# DSS0_VID1 register map
Vendor: Texas Instruments
Peripheral module from a debugger description file (folder J7ES).
Registers are 32-bit, access per field, reset 0x0 unless marked. A register's access mark holds for its fields unless they carry their own. Offsets are as the file gives them; lines under a group give offsets from that group; [hi:lo] are bit positions; {n}, {i} and the like mark numbered series; 'fields as' and 'values as' point back to an identical list; <NAME> marks a mode.

## DSS0_VID1
0x00 DSS0_VID_ACCUH_0 — The register configures the resize accumulator init values for horizontal up/down-sampling of the video window. DISPC_VIDx_ACCU__0 & DISPC_VIDx_ACCU__1 for ping-pong mechanism with external trigger, based on the field polarity. This register is used for ARGB and Y in YUV420/YUV422. Shadow register
  [23:0] HORIZONTALACCU rw — Horizontal initialization accu signed value
0x04 DSS0_VID_ACCUH_1 — The register configures the resize accumulator init values for horizontal up/down-sampling of the video window. DISPC_VIDx_ACCU__0 & DISPC_VIDx_ACCU__1 for ping-pong mechanism with external trigger, based on the field polarity. This register is used for ARGB and Y in YUV420/YUV422. Shadow register
  fields as DSS0_VID_ACCUH_0
0x08 DSS0_VID_ACCUH2_0 — The register configures the resize accumulator init value for horizontal up/down-sampling of the video window. DISPC_VID n_ACCU2__0 & DISPC_VID n_ACCU2__1 for ping-pong mechanism with external trigger, based on the field polarity. This register is used for U/V components in YUV420/YUV422. It is not used when the input format is any RGB format. Shadow register
  fields as DSS0_VID_ACCUH_0
0x0C DSS0_VID_ACCUH2_1 — The register configures the resize accumulator init value for horizontal up/down-sampling of the video window. DISPC_VID n_ACCU2__0 & DISPC_VID n_ACCU2__1 for ping-pong mechanism with external trigger, based on the field polarity. This register is used for U/V components in YUV420/YUV422. It is not used when the input format is any RGB format. Shadow register
  fields as DSS0_VID_ACCUH_0
0x10 DSS0_VID_ACCUV_0 — The register configures the resize accumulator init values for horizontal and vertical up/down-sampling of the video window. DISPC_VIDx_ACCU__0 & DISPC_VIDx_ACCU__1 for ping-pong mechanism with external trigger, based on the field polarity. It is used for ARGB and Y in YUV420/YUV422. Shadow register
  [23:0] VERTICALACCU rw — Vertical initialization accu signed value
0x14 DSS0_VID_ACCUV_1 — The register configures the resize accumulator init values for horizontal and vertical up/down-sampling of the video window. DISPC_VIDx_ACCU__0 & DISPC_VIDx_ACCU__1 for ping-pong mechanism with external trigger, based on the field polarity. It is used for ARGB and Y in YUV420/YUV422. Shadow register
  [23:0] VERTICALACCU rw — Vertical initialization accu signed value
0x18 DSS0_VID_ACCUV2_0 — The register configures the resize accumulator init value for vertical up/down-sampling of the video window. ACCU2__0 & ACCU2__1 for ping-pong mechanism with external trigger, based on the field polarity. It is used for U/V components for YUV420. It is not used when the input format is any RGB format or YUV422. Shadow register
  [23:0] VERTICALACCU rw — Vertical initialization accu signed value
0x1C DSS0_VID_ACCUV2_1 — The register configures the resize accumulator init value for vertical up/down-sampling of the video window. ACCU2__0 & ACCU2__1 for ping-pong mechanism with external trigger, based on the field polarity. It is used for U/V components for YUV420. It is not used when the input format is any RGB format or YUV422. Shadow register
  [23:0] VERTICALACCU rw — Vertical initialization accu signed value
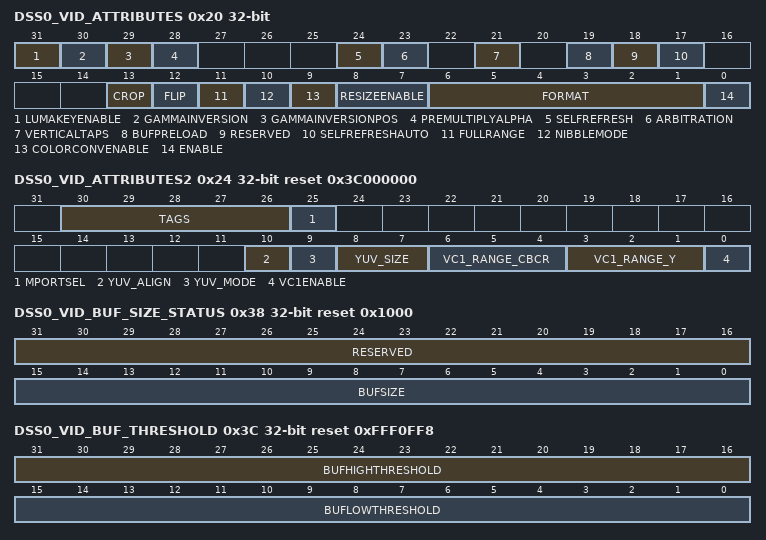
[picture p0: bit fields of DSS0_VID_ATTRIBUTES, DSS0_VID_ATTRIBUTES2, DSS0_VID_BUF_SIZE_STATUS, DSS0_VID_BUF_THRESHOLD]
0x20 DSS0_VID_ATTRIBUTES — The register configures the of the video window. Shadow register
  [31] LUMAKEYENABLE rw — Enable Luma Key transparency matching
  [30] GAMMAINVERSION rw — Inverse Gamma support [using the CLUT table]
  [29] GAMMAINVERSIONPOS rw — Position of Inverse Gamma operation
  [28] PREMULTIPLYALPHA rw — The field configures the DISPC VID to process incoming data as premultiplied alpha data or non premultiplied alpha data.
  [24] SELFREFRESH rw — Enables the self refresh of the video window, from its own DMA buffer only
  [23] ARBITRATION rw — Determines the priority of the video pipeline.
  [21] VERTICALTAPS rw — Video Vertical Resize Tap Number.
  [19] BUFPRELOAD rw — Video
  [18] RESERVED ro — Write 0's for future compatibility.
  [17] SELFREFRESHAUTO rw — Automatic self refresh mode
  [13] CROP rw — Enables cropping operation at the output of Video Pipeline
  [12] FLIP rw — Describes the frame buffer flip operation
  [11] FULLRANGE rw — Color Space Conversion full range setting
  [10] NIBBLEMODE rw — Video Nibble mode [only for
  [9] COLORCONVENABLE rw — Enable the color space conversion.
  [8:7] RESIZEENABLE rw — Video Resize Enable
  [6:1] FORMAT rw — Video Format.
  [0] ENABLE rw — Video pipeline Enable
0x24 DSS0_VID_ATTRIBUTES2 reset 0x3C000000 — The register configures the of the video window. Shadow register
  [30:26] TAGS rw — Number of OCP TAGS to be used for the pipeline [from 0x0 to 0xF].
  [25] MPORTSEL rw — Master-Port Selection.
  [10] YUV_ALIGN rw — Alignment [MSB or LSB align] for unpacked 10b/12b YUV data
  [9] YUV_MODE rw — Mode of packing for YUV data [only for 10b/12b formats]
  [8:7] YUV_SIZE rw
  [6:4] VC1_RANGE_CBCR rw — Defines the VC1 range value for the CbCr component from 0 to 7
  [3:1] VC1_RANGE_Y rw — Defines the VC1 range value for the Y component from 0 to 7
  [0] VC1ENABLE rw — Enable/disable the VC1 range mapping processing.
0x28 DSS0_VID_BA_0 rw — The register configures the base address of the single video buffer. In case of single plane ARGB or YUV, this is the BA. In case of two plane YUV, this is the BA_Y. In case of two plane RGB565-A8, this is the BA_Alpha. BA__0 & BA__1 for ping-pong mechanism with external trigger, based on the field polarity otherwise only BA__0 is used. Shadow register
  [31:0] BA — Video base address.
0x2C DSS0_VID_BA_1 rw — The register configures the base address of the single video buffer. In case of single plane ARGB or YUV, this is the BA. In case of two plane YUV, this is the BA_Y. In case of two plane RGB565-A8, this is the BA_Alpha. BA__0 & BA__1 for ping-pong mechanism with external trigger, based on the field polarity otherwise only BA__0 is used. Shadow register
  [31:0] BA — Video base address.
0x30 DSS0_VID_BA_UV_0 rw — The register configures the base address of the UV buffer for two plane YUV or RGB buffer for two plane RGB565-A8, for the video window. BA_UV__0 & BA_UV__1 for ping-pong mechanism with external trigger, based on the field polarity otherwise only BA_UV__0 is used. Shadow register
  [31:0] BA — Video base address aligned on 16-bit boundary Base address of the UV video buffer used only in case of YUV420-NV12
0x34 DSS0_VID_BA_UV_1 rw — The register configures the base address of the UV buffer for two plane YUV or RGB buffer for two plane RGB565-A8, for the video window. BA_UV__0 & BA_UV__1 for ping-pong mechanism with external trigger, based on the field polarity otherwise only BA_UV__0 is used. Shadow register
  fields as DSS0_VID_BA_UV_0
0x38 DSS0_VID_BUF_SIZE_STATUS ro reset 0x1000 — The register returns the Video buffer for the video pipeline
  [31:16] RESERVED — Write 0's for future compatibility Reads return 0
  [15:0] BUFSIZE — Video DMA buffer
0x3C DSS0_VID_BUF_THRESHOLD rw reset 0xFFF0FF8 — The register configures the video buffer associated with the video pipeline. Shadow register
  [31:16] BUFHIGHTHRESHOLD — DMA buffer High Threshold.
  [15:0] BUFLOWTHRESHOLD — DMA buffer Low Threshold.
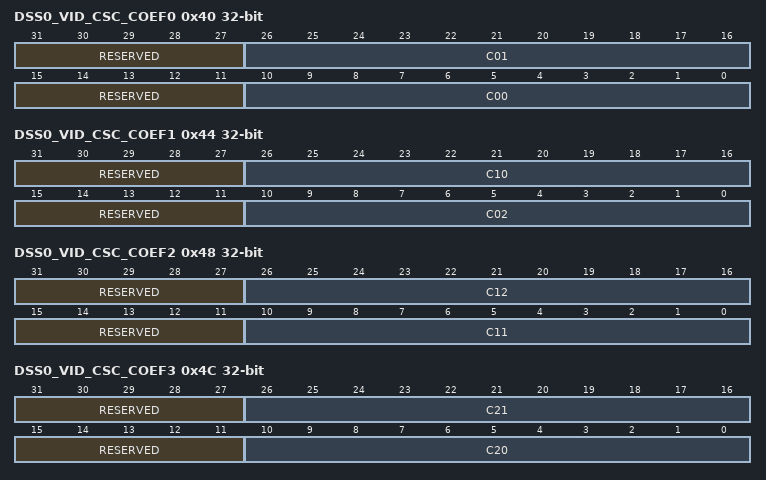
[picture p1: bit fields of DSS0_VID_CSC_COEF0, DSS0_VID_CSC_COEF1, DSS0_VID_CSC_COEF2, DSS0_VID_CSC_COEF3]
0x40 DSS0_VID_CSC_COEF0 — The register configures the color space conversion matrix coefficients. Shadow register
  [31:27] RESERVED ro — Write 0's for future compatibility Reads return 0
  [26:16] C01 rw — C01 Coefficient.
  [15:11] RESERVED ro — Write 0's for future compatibility Reads return 0
  [10:0] C00 rw — C00 Coefficient.
0x44 DSS0_VID_CSC_COEF1 — The register configures the color space conversion matrix coefficients. Shadow register
  [31:27] RESERVED ro — Write 0's for future compatibility Reads return 0
  [26:16] C10 rw — C10 Coefficient.
  [15:11] RESERVED ro — Write 0's for future compatibility Reads return 0
  [10:0] C02 rw — C02 Coefficient.
0x48 DSS0_VID_CSC_COEF2 — The register configures the color space conversion matrix coefficients. Shadow register
  [31:27] RESERVED ro — Write 0's for future compatibility Reads return 0
  [26:16] C12 rw — C12 Coefficient.
  [15:11] RESERVED ro — Write 0's for future compatibility Reads return 0
  [10:0] C11 rw — C11 Coefficient.
0x4C DSS0_VID_CSC_COEF3 — The register configures the color space conversion matrix coefficients. Shadow register
  [31:27] RESERVED ro — Write 0's for future compatibility Reads return 0
  [26:16] C21 rw — C21 coefficient.
  [15:11] RESERVED ro — Write 0's for future compatibility Reads return 0
  [10:0] C20 rw — C20 coefficient.
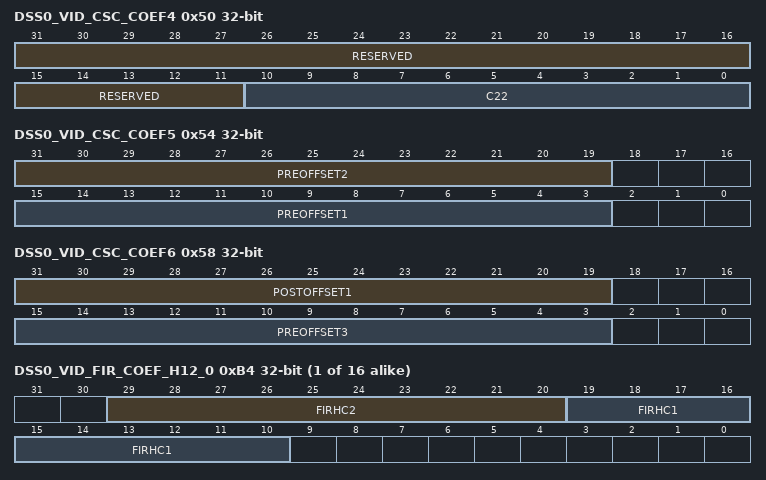
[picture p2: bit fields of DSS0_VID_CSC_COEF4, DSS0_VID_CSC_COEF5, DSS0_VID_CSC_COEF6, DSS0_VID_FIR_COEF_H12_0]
0x50 DSS0_VID_CSC_COEF4 — The register configures the color space conversion matrix coefficients. Shadow register
  [31:11] RESERVED ro — Write 0's for future compatibility Reads return 0
  [10:0] C22 rw — C22 Coefficient.
0x54 DSS0_VID_CSC_COEF5 — The register configures the color space conversion matrix coefficients. Shadow register
  [31:19] PREOFFSET2 rw — Row-2 pre-offset.
  [15:3] PREOFFSET1 rw — Row1 pre-offset.
0x58 DSS0_VID_CSC_COEF6 — The register configures the color space conversion matrix coefficients. Shadow register
  [31:19] POSTOFFSET1 rw — Row-1 post-offset.
  [15:3] PREOFFSET3 rw — Row-3 pre-offset.
0x5C DSS0_VID_FIRH reset 0x200000 — The register configures the resize factor for horizontal up/down-sampling of the video window. It is used for ARGB and Y setting. Shadow register
  [23:0] FIRHINC rw — Horizontal increment of the up/down-sampling filter.
0x60 DSS0_VID_FIRH2 reset 0x200000 — The register configures the resize factor for horizontal up/down-sampling of the video window. It is used for U/V components for YUV 422 and 420 input formats. It is not used if input format is any RGB format. Shadow register
  [23:0] FIRHINC rw — Horizontal increment of the up/down-sampling filter for Cb and Cr.
0x64 DSS0_VID_FIRV reset 0x200000 — The register configures the resize factor for vertical up/down-sampling of the video window. It is used for ARGB and Y setting. Shadow register
  [23:0] FIRVINC rw — Vertical increment of the up/down-sampling filter.
0x68 DSS0_VID_FIRV2 reset 0x200000 — The register configures the resize factor for vertical up/down-sampling of the video window. It is used for U/V components for YUV420 input format. It is not used when the input format is any RGB format or YUV422 format. Shadow register.
  [23:0] FIRVINC rw — Vertical increment of the up/down-sampling filter for Cb and Cr.
{0x6C+4i} DSS0_VID_FIR_COEF_H0_{i} (i=0..8) — The bank of registers configures the up/down-scaling coefficients for the horizontal resize of the video picture associated with the video window for the 16 phases. It is used for ARGB and Y setting. Shadow register
  [9:0] FIRHC0 rw — Unsigned coefficient C0 for the horizontal up/down-scaling with the phase {i}
{0x90+4i} DSS0_VID_FIR_COEF_H0_C_{i} (i=0..8) — The bank of registers configures the up/down-scaling coefficients for the horizontal resize of the video picture associated with the video window for the phases from 0 to 15. It is used for Crb and Cr setting. It is used only when the pixel format at the input of the filter is one of the YUV formats. When the register is not used by the HW, any value can be used for the bit-fields. Shadow register
  fields as DSS0_VID_FIR_COEF_H0_0
{0xB4+4i} DSS0_VID_FIR_COEF_H12_{i} (i=0..15) — The bank of registers configures the up/down-scaling coefficients for the horizontal resize of the video picture associated with the video window for the 16 phases. It is used for ARGB and Y setting. Shadow register
  [29:20] FIRHC2 rw — Signed coefficient C2 for the horizontal up/down-scaling with the phase {i}
  [19:10] FIRHC1 rw — Signed coefficient C1 for the horizontal up/down-scaling with the phase {i}
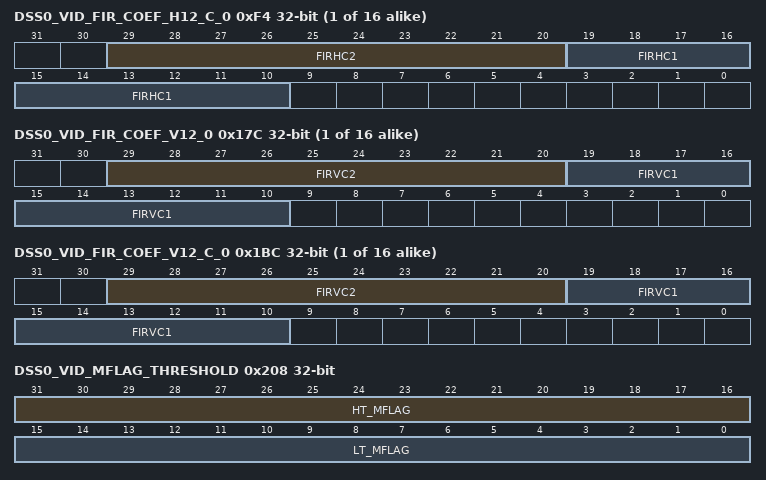
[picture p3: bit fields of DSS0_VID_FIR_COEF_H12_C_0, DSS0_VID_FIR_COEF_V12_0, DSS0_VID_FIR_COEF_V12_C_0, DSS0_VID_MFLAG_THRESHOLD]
{0xF4+4i} DSS0_VID_FIR_COEF_H12_C_{i} (i=0..15) — The bank of registers configures the up/down-scaling coefficients for the horizontal resize of the video picture associated with the video window for the phases from 0 to 15. It is used for Crb and Cr setting. It is used only when the pixel format at the input of the filter is one of the YUV formats. When the register is not used by the HW, any value can be used for the bit-fields. Shadow register
  fields as DSS0_VID_FIR_COEF_H12_0
{0x134+4i} DSS0_VID_FIR_COEF_V0_{i} (i=0..8) — The bank of registers configures the up/down-scaling coefficients for the vertical resize of the video picture associated with the video window for the 16 phases. It is used for ARGB and Y setting. Shadow register
  [9:0] FIRVC0 rw — Unsigned coefficient C0 for the vertical up/down-scaling with the phase {i}
{0x158+4i} DSS0_VID_FIR_COEF_V0_C_{i} (i=0..8) — The bank of registers configures the up/down-scaling coefficients for the vertical resize of the video picture associated with the video window for the phases from 0 to 15. It is used for Crb and Cr setting. It is used only when the pixel format at the input of the filter is one of the YUV formats. When the register is not used by the HW, any value can be used for the bit-fields. Shadow register
  fields as DSS0_VID_FIR_COEF_V0_0
{0x17C+4i} DSS0_VID_FIR_COEF_V12_{i} (i=0..15) — The bank of registers configures the up/down-scaling coefficients for the vertical resize of the video picture associated with the video window for the 16 phases. It is used for ARGB and Y setting. Shadow register
  [29:20] FIRVC2 rw — Signed coefficient C2 for the vertical up/down-scaling with the phase {i}
  [19:10] FIRVC1 rw — Signed coefficient C1 for the vertical up/down-scaling with the phase {i}
{0x1BC+4i} DSS0_VID_FIR_COEF_V12_C_{i} (i=0..15) — The bank of registers configures the up/down-scaling coefficients for the vertical resize of the video picture associated with the video window for the phases from 0 to 15. It is used for Crb and Cr setting. It is used only when the pixel format at the input of the filter is one of the YUV formats. When the register is not used by the HW, any value can be used for the bit-fields. Shadow register
  fields as DSS0_VID_FIR_COEF_V12_0
0x1FC DSS0_VID_GLOBAL_ALPHA reset 0xFF — The register defines the global alpha value for the video pipeline. Shadow register
  [7:0] GLOBALALPHA rw — Global alpha value from 0 to 255.
0x208 DSS0_VID_MFLAG_THRESHOLD rw — Register
  [31:16] HT_MFLAG — MFlag High Threshold
  [15:0] LT_MFLAG — MFlag Low Threshold
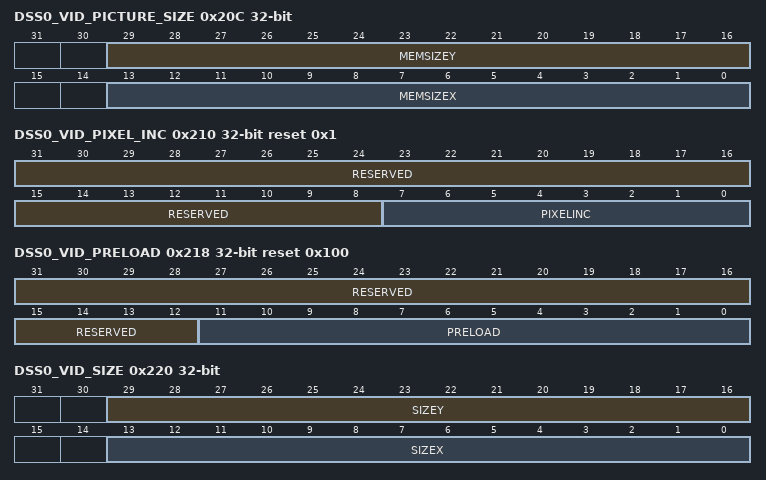
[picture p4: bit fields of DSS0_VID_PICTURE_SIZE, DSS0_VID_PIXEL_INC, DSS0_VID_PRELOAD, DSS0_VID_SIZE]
0x20C DSS0_VID_PICTURE_SIZE rw — The register configures the of the video picture associated with the video layer before up/down-scaling. Shadow register
  [29:16] MEMSIZEY — Number of lines of the video picture Encoded value [from 1 to 16384] to specify the number of lines of the video picture in memory [program to value minus one] When predecimation is set, the value represents the
  [13:0] MEMSIZEX — Number of pixels of the video picture Encoded value [from 1 to 16384] to specify the number of pixels of the video picture in memory [program to value minus one].
0x210 DSS0_VID_PIXEL_INC reset 0x1 — The register configures the number of bytes to increment between two pixels for the buffer associated with the video window. Shadow register
  [31:8] RESERVED ro — Write 0's for future compatibility Reads return 0
  [7:0] PIXELINC rw — Number of bytes to increment between two pixels Encoded unsigned value [from 1 to 255] to specify the number of bytes between two pixels in the video buffer.
0x218 DSS0_VID_PRELOAD reset 0x100 — The register configures the DMA buffer of the video pipeline. Shadow register
  [31:12] RESERVED ro — Write 0's for future compatibility Reads return 0
  [11:0] PRELOAD rw — DMA buffer
0x21C DSS0_VID_ROW_INC rw reset 0x1 — The register configures the number of bytes to increment at the end of the row for the buffer associated with the video window. For YUV420 formats this corresponds to the Y Buffer. Shadow register
  [31:0] ROWINC — Number of bytes to increment at the end of the row Encoded signed value [from -2
0x220 DSS0_VID_SIZE rw — The register configures the of the video window. Shadow register
  [29:16] SIZEY — Number of lines of the video window Encoded value [from 1 to 16384] to specify the number of lines of the video window [program
  [13:0] SIZEX — Number of pixels of the video window Encoded value [from 1 to 16384] to specify the number of pixels of the video window [program
0x22C DSS0_VID_BA_EXT_0 — The register configures the 16-bit base address extension. It is the base-address of the single video buffer for single plane ARGB or YUV. For the Y buffer for two plane YUV. For the Alpha buffer for two plane RGB565-A8. 0 & 1 : For ping-pong mechanism with external trigger, based on the field polarity. Shadow register
  [15:0] BA_EXT rw — Video base address extension [16 bits].
0x230 DSS0_VID_BA_EXT_1 — The register configures the 16-bit base address extension. It is the base-address of the single video buffer for single plane ARGB or YUV. For the Y buffer for two plane YUV. For the Alpha buffer for two plane RGB565-A8. 0 & 1 : For ping-pong mechanism with external trigger, based on the field polarity. Shadow register
  [15:0] BA_EXT rw — Video base address extension [16 bits].
0x234 DSS0_VID_BA_UV_EXT_0 — The register configures the 16-bit base address extension of the UV buffer for two plane YUV or the RGB buffer for two plane RGB565-A8. 0 & 1 : For ping-pong mechanism with external trigger, based on the field polarity. Shadow register
  [15:0] BA_UV_EXT rw — Video base address extension [16 bits].
0x238 DSS0_VID_BA_UV_EXT_1 — The register configures the 16-bit base address extension of the UV buffer for two plane YUV or the RGB buffer for two plane RGB565-A8. 0 & 1 : For ping-pong mechanism with external trigger, based on the field polarity. Shadow register
  [15:0] BA_UV_EXT rw — Video base address extension [16 bits].
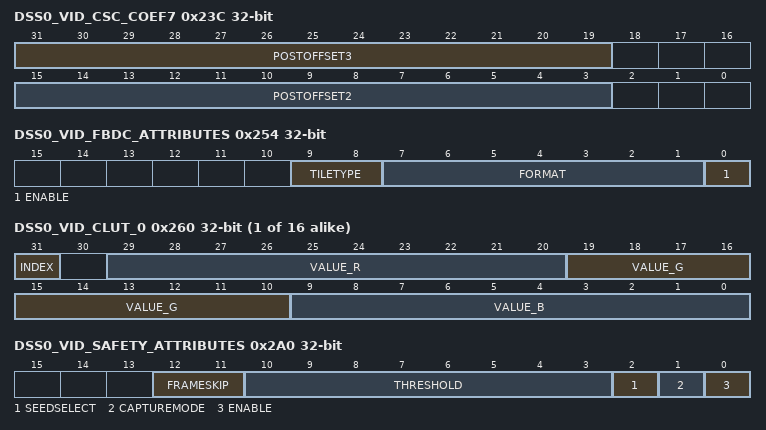
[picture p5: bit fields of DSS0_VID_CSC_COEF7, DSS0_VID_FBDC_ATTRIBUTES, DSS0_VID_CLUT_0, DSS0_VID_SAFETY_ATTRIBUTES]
0x23C DSS0_VID_CSC_COEF7 — The register configures the color space conversion matrix coefficients. Shadow register
  [31:19] POSTOFFSET3 rw — Row-3 post-offset.
  [15:3] POSTOFFSET2 rw — Row-2 post-offset.
0x248 DSS0_VID_ROW_INC_UV rw reset 0x1 — The register configures the number of bytes to increment at the end of the row for the UV buffer associated with the video window for YUV420 formats. For non-YUV420 formats this register is unused. Shadow register
  fields as DSS0_VID_ROW_INC
0x24C DSS0_VID_TILE rw — Defines the characteristics of the position of the first pixel inside the compressed frame buffer. In case of non-compressed frame buffer, the register is not used.
  [22:0] TILEINDEX — Defines the
0x250 DSS0_VID_TILE2 — Defines the number of tiles in the frame buffer. In case of non-compressed frame buffer, the register is not used.
  [22:0] NUM_TILES rw — Defines the total number of tiles in the compressed frame buffer
0x254 DSS0_VID_FBDC_ATTRIBUTES rw — Defines the for the compression engine -FBDC
  [9:8] TILETYPE — FBDC
  [7:1] FORMAT — FBDC format
  [0] ENABLE — Frame Buffer Compression is Enabled.
0x258 DSS0_VID_FBDC_CLEAR_COLOR rw — Defines the Clear Color value to be used for the channel in FBDC
  [31:0] CLEARCOLOR
{0x260+4i} DSS0_VID_CLUT_{i} wo (i=0..15) — The register configures the Color Look Up Table CLUT for VID pipeline. CLUT is used in conjunction with bitmap formats
  [31] INDEX — Write 1 to reset the index
  [29:20] VALUE_R
  [19:10] VALUE_G
  [9:0] VALUE_B
0x2A0 DSS0_VID_SAFETY_ATTRIBUTES — The register configures the safety sub-region. Shadow register
  [12:11] FRAMESKIP rw — Indicates which frames to be skipped while doing FRAMEFREEZE or DATACHECK [Useful for interlaced displays].
  [10:3] THRESHOLD rw — Allowed maximum number of frames with the same frame signature.
  [2] SEEDSELECT rw — Initial seed selection control
  [1] CAPTUREMODE rw — Mode of operation of the safety check module
  [0] ENABLE rw — Safety check Enable for the region.
0x2A4 DSS0_VID_SAFETY_CAPT_SIGNATURE ro — The register captures the signature from the MISR of the safety sub-region. Shadow register
  [31:0] SIGNATURE — The register configures the reference signature of the safety sub-region.
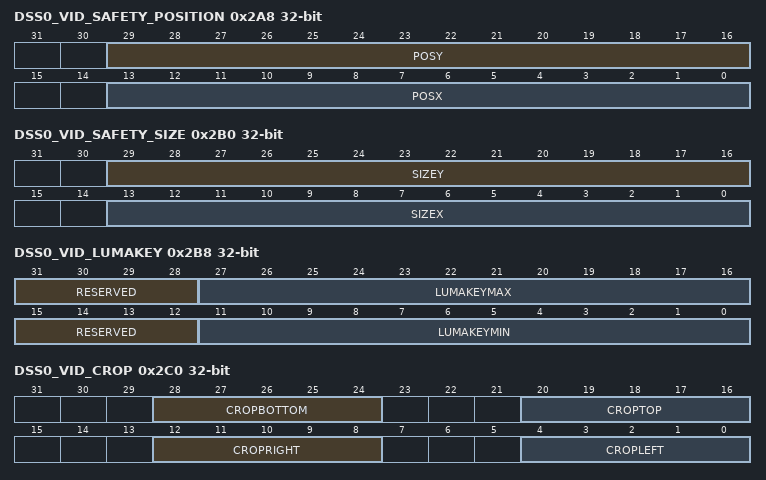
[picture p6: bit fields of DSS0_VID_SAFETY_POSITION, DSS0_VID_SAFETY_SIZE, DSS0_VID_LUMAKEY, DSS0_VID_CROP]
0x2A8 DSS0_VID_SAFETY_POSITION rw — The register configures the position of the safety sub-region. Shadow register
  [29:16] POSY — Y position of the safety sub-region.
  [13:0] POSX — X position of the safety sub-region.
0x2AC DSS0_VID_SAFETY_REF_SIGNATURE rw — The register configures the reference signature of the safety sub-region. Shadow register
  fields as DSS0_VID_SAFETY_CAPT_SIGNATURE
0x2B0 DSS0_VID_SAFETY_SIZE rw — The register configures the of the safety sub-region. Shadow register
  [29:16] SIZEY — Height of the safety sub-region.
  [13:0] SIZEX — Width of the safety sub-region.
0x2B4 DSS0_VID_SAFETY_LFSR_SEED rw — The register configures the seed [initial value] of the MISR. Otherwise, the MISR is initialized with 0xFFFF_FFFF. Shadow register
  [31:0] SEED — The register configures the seed [initial value] of the MISR.
0x2B8 DSS0_VID_LUMAKEY — The register configures the LUMA KEY transparency min and max values. Shadow register
  [31:28] RESERVED ro — Write 0's for future compatibility Reads return 0
  [27:16] LUMAKEYMAX rw — 12b luma_key_max value
  [15:12] RESERVED ro — Write 0's for future compatibility Reads return 0
  [11:0] LUMAKEYMIN rw — 12b luma_key_min value
0x2BC DSS0_VID_DMA_BUFSIZE reset 0x4 — The register configures the DMA buffer allocated to the pipeline - New Shared memory feature
  [4:0] BUFSIZE rw — DMA buffer
0x2C0 DSS0_VID_CROP rw — Defines the for the output cropping in Video Pipe
  [28:24] CROPBOTTOM, [20:16] CROPTOP, [12:8] CROPRIGHT, [4:0] CROPLEFT
0x2C4 DSS0_VID_SECURE — Security bit settings for the sub-module
  [0] SECURE rw
0x2C8 DSS0_VID_PIPE_GO — PIPE GO bit settings
  [0] GOBIT rw
